# MDR1986VK01 register map
File version: 1.0.2
Registers are 32-bit, read-write, no defined reset value unless marked. A register's access mark holds for its fields unless they carry their own. Offsets are from the block's base; [hi:lo] are bit positions; {n}, {i} and the like mark numbered series; 'fields as' and 'values as' point back to an identical list.

## MDR_CLK — MDR_CLK description
Base 0x40000000
0x00 KEY — KEY description
0x04 MAX_CLK — MAX_CLK description
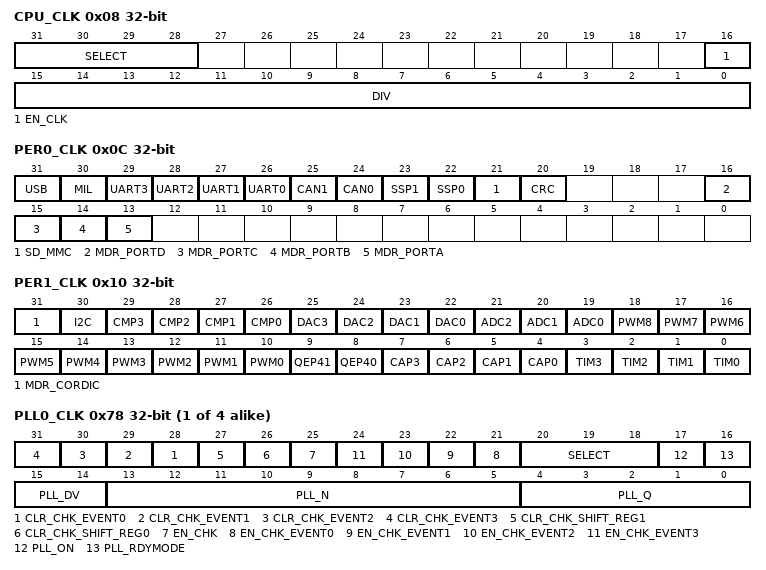
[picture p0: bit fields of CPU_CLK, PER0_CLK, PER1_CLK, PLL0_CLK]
0x08 CPU_CLK — CPU_CLK description
  [31:28] SELECT — SELECT description
  [16] EN_CLK — EN_CLK description
  [15:0] DIV — DIV description
0x0C PER0_CLK — PER0_CLK description
  [31] USB — USB description
  [30] MIL — MIL description
  [n+26] UART{n} (n=0..3) — UART{n} description
  [25] CAN1 — CAN1 description
  [24] CAN0 — CAN0 description
  [23] SSP1 — SSP1 description
  [22] SSP0 — SSP0 description
  [21] SD_MMC — SD_MMC description
  [20] CRC — CRC description
  [16] MDR_PORTD — MDR_PORTD description
  [15] MDR_PORTC — MDR_PORTC description
  [14] MDR_PORTB — MDR_PORTB description
  [13] MDR_PORTA — MDR_PORTA description
0x10 PER1_CLK — PER1_CLK description
  [31] MDR_CORDIC — MDR_CORDIC description
  [30] I2C — I2C description
  [n+26] CMP{n} (n=0..3) — CMP{n} description
  [n+22] DAC{n} (n=0..3) — DAC{n} description
  [21] ADC2 — ADC2 description
  [20] ADC1 — ADC1 description
  [19] ADC0 — ADC0 description
  [n+10] PWM{n} (n=0..8) — PWM{n} description
  [9] QEP41 — QEP41 description
  [8] QEP40 — QEP40 description
  [n+4] CAP{n} (n=0..3) — CAP{n} description
  [n] TIM{n} (n=0..3) — TIM{n} description
{0x14+4i} CPU_CHK{i} (i=0..2) — CPU_CHK{i} description
0x20 CPU_STAT — CPU_STAT description
{0x78+0x14*i} PLL{i}_CLK (i=0..3) — PLL{i}_CLK description
  [n+28] CLR_CHK_EVENT{n} (n=0..3) — CLR_CHK_EVENT{n} description
  [27] CLR_CHK_SHIFT_REG1 — CLR_CHK_SHIFT_REG1 description
  [26] CLR_CHK_SHIFT_REG0 — CLR_CHK_SHIFT_REG0 description
  [25] EN_CHK — EN_CHK description
  [n+21] EN_CHK_EVENT{n} (n=0..3) — EN_CHK_EVENT{n} description
  [20:18] SELECT — SELECT description
  [17] PLL_ON — PLL_ON description
  [16] PLL_RDYMODE — PLL_RDYMODE description
  [15:14] PLL_DV — PLL_DV description
  [13:5] PLL_N — PLL_N description
  [4:0] PLL_Q — PLL_Q description
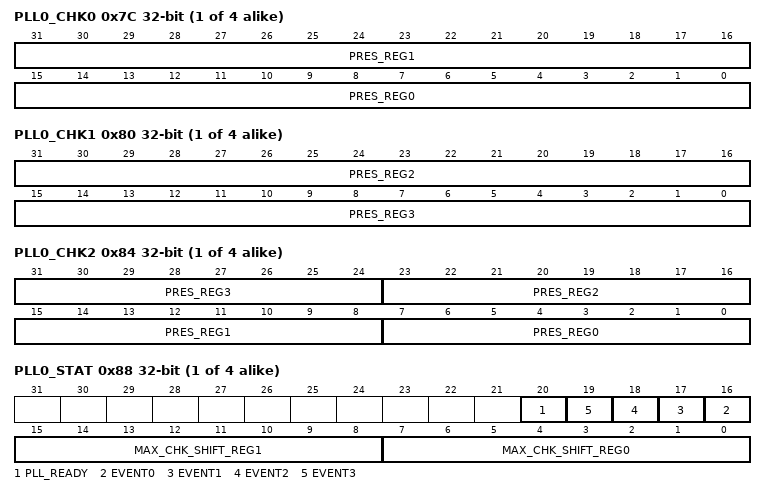
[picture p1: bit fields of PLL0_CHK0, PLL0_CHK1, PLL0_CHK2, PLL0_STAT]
{0x7C+0x14*i} PLL{i}_CHK0 (i=0..3) — PLL{i}_CHK0 description
  [31:16] PRES_REG1 — PRES_REG1 description
  [15:0] PRES_REG0 — PRES_REG0 description
{0x80+0x14*i} PLL{i}_CHK1 (i=0..3) — PLL{i}_CHK1 description
  [31:16] PRES_REG2 — PRES_REG2 description
  [15:0] PRES_REG3 — PRES_REG3 description
{0x84+0x14*i} PLL{i}_CHK2 (i=0..3) — PLL{i}_CHK2 description
  [8n+7:8n] PRES_REG{n} (n=0..3) — PRES_REG{n} description
{0x88+0x14*i} PLL{i}_STAT (i=0..3) — PLL{i}_STAT description
  [20] PLL_READY — PLL_READY description
  [n+16] EVENT{n} (n=0..3) — EVENT{n} description
  [15:8] MAX_CHK_SHIFT_REG1 — MAX_CHK_SHIFT_REG1 description
  [7:0] MAX_CHK_SHIFT_REG0 — MAX_CHK_SHIFT_REG0 description
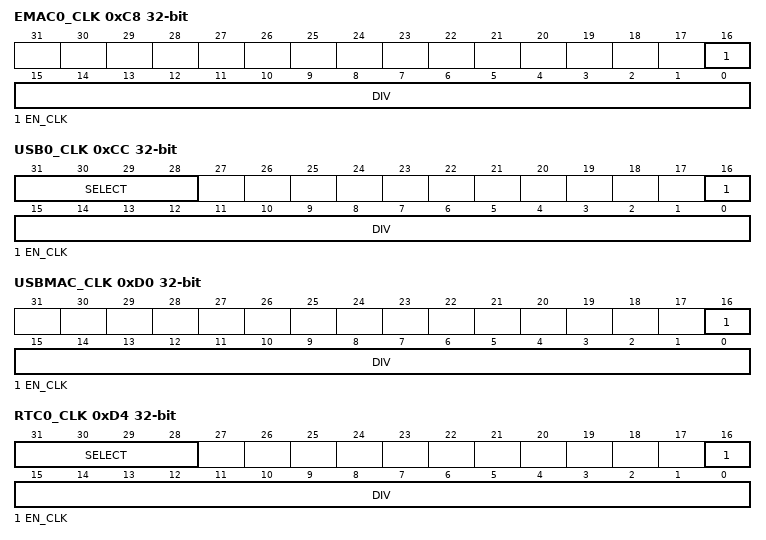
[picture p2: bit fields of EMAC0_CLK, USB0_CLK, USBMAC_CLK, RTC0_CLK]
0xC8 EMAC0_CLK — EMAC0_CLK description
  [16] EN_CLK — EN_CLK description
  [15:0] DIV — DIV description
0xCC USB0_CLK — USB0_CLK description
  fields as CPU_CLK
0xD0 USBMAC_CLK — USBMAC_CLK description
  [16] EN_CLK — EN_CLK description
  [15:0] DIV — DIV description
0xD4 RTC0_CLK — RTC0_CLK description
  fields as CPU_CLK
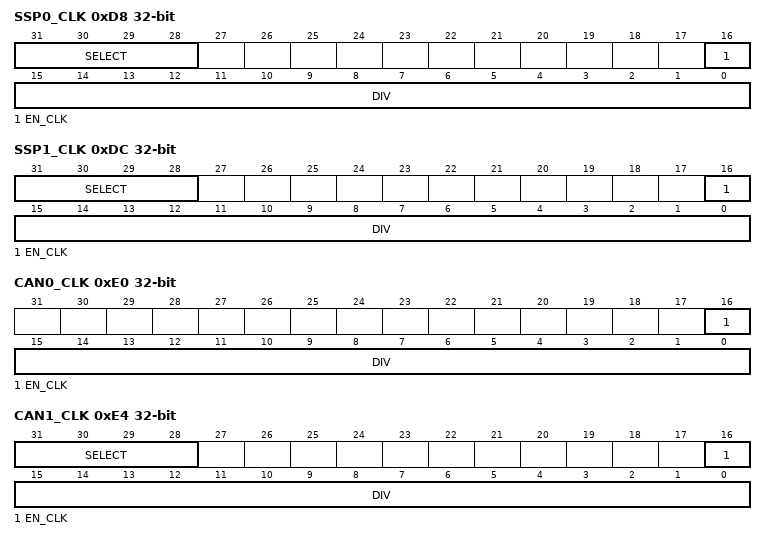
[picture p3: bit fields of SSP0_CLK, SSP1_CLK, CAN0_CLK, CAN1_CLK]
0xD8 SSP0_CLK — SSP0_CLK description
  fields as CPU_CLK
0xDC SSP1_CLK — SSP1_CLK description
  fields as CPU_CLK
0xE0 CAN0_CLK — CAN0_CLK description
  [16] EN_CLK — EN_CLK description
  [15:0] DIV — DIV description
0xE4 CAN1_CLK — CAN1_CLK description
  fields as CPU_CLK
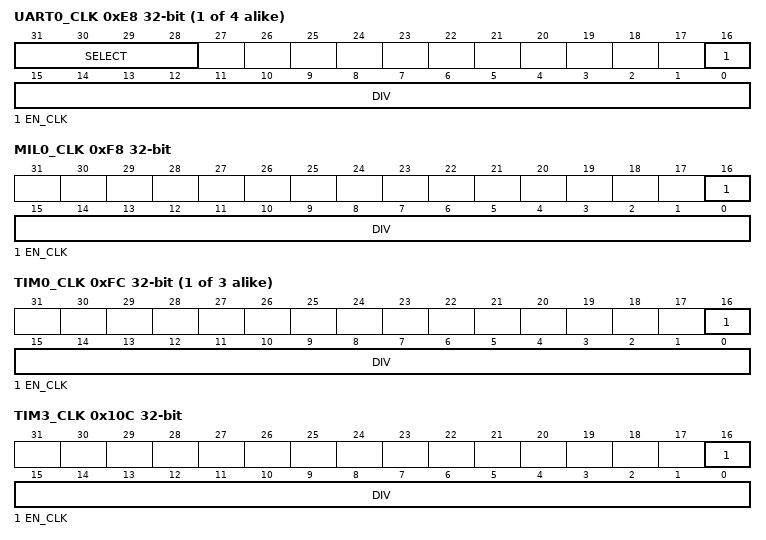
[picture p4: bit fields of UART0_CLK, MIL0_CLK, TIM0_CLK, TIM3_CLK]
{0xE8+4i} UART{i}_CLK (i=0..3) — UART{i}_CLK description
  fields as CPU_CLK
0xF8 MIL0_CLK — MIL0_CLK description
  [16] EN_CLK — EN_CLK description
  [15:0] DIV — DIV description
{0xFC+4i} TIM{i}_CLK (i=0..2) — TIM{i}_CLK description
  [16] EN_CLK — EN_CLK description
  [15:0] DIV — DIV description
0x10C TIM3_CLK — TIM3_CLK description
  [16] EN_CLK — EN_CLK description
  [15:0] DIV — DIV description
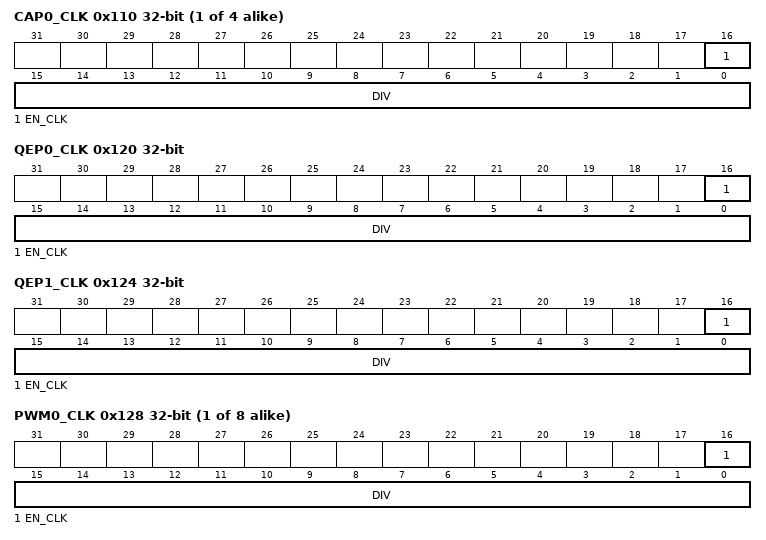
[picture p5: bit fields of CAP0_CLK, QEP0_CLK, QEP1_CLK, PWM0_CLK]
{0x110+4i} CAP{i}_CLK (i=0..3) — CAP{i}_CLK description
  [16] EN_CLK — EN_CLK description
  [15:0] DIV — DIV description
0x120 QEP0_CLK — QEP0_CLK description
  [16] EN_CLK — EN_CLK description
  [15:0] DIV — DIV description
0x124 QEP1_CLK — QEP1_CLK description
  [16] EN_CLK — EN_CLK description
  [15:0] DIV — DIV description
{0x128+4i} PWM{i}_CLK (i=0..7) — PWM{i}_CLK description
  [16] EN_CLK — EN_CLK description
  [15:0] DIV — DIV description
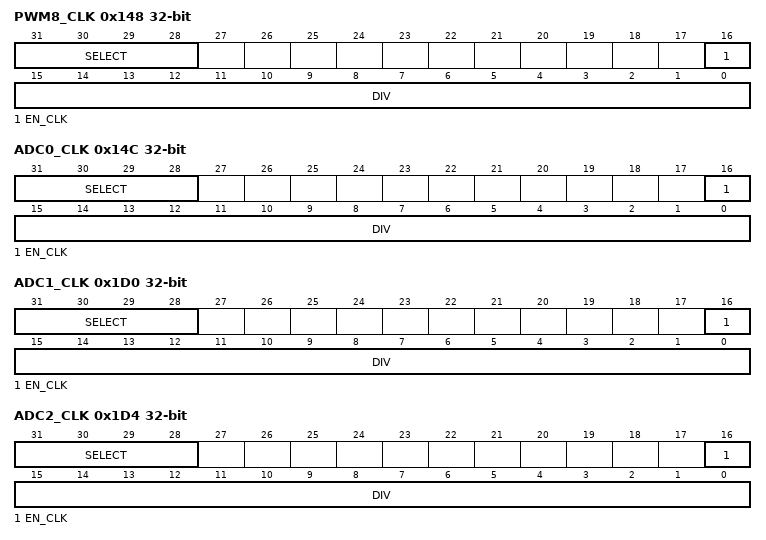
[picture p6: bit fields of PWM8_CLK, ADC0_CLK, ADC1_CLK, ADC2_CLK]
0x148 PWM8_CLK — PWM8_CLK description
  fields as CPU_CLK
0x14C ADC0_CLK — ADC0_CLK description
  fields as CPU_CLK
0x1D0 ADC1_CLK — ADC1_CLK description
  fields as CPU_CLK
0x1D4 ADC2_CLK — ADC2_CLK description
  fields as CPU_CLK
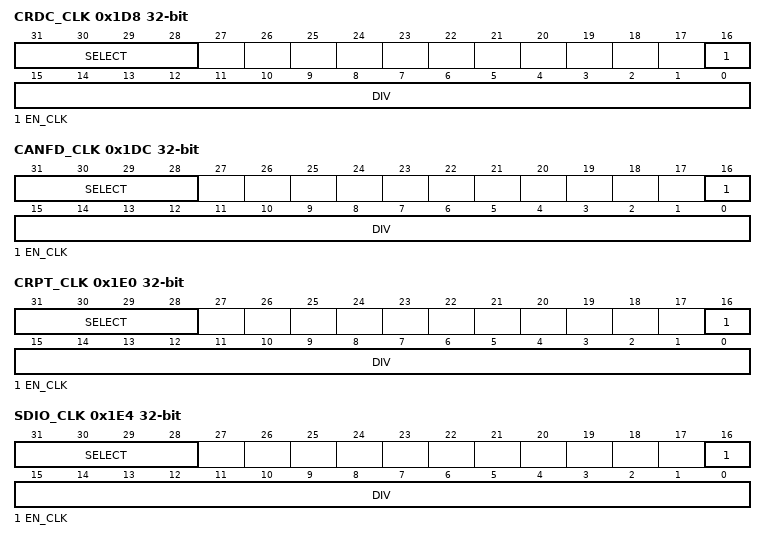
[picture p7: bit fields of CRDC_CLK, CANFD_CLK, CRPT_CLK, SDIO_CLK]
0x1D8 CRDC_CLK — CRDC_CLK description
  fields as CPU_CLK
0x1DC CANFD_CLK — CANFD_CLK description
  fields as CPU_CLK
0x1E0 CRPT_CLK — CRPT_CLK description
  fields as CPU_CLK
0x1E4 SDIO_CLK — SDIO_CLK description
  fields as CPU_CLK
